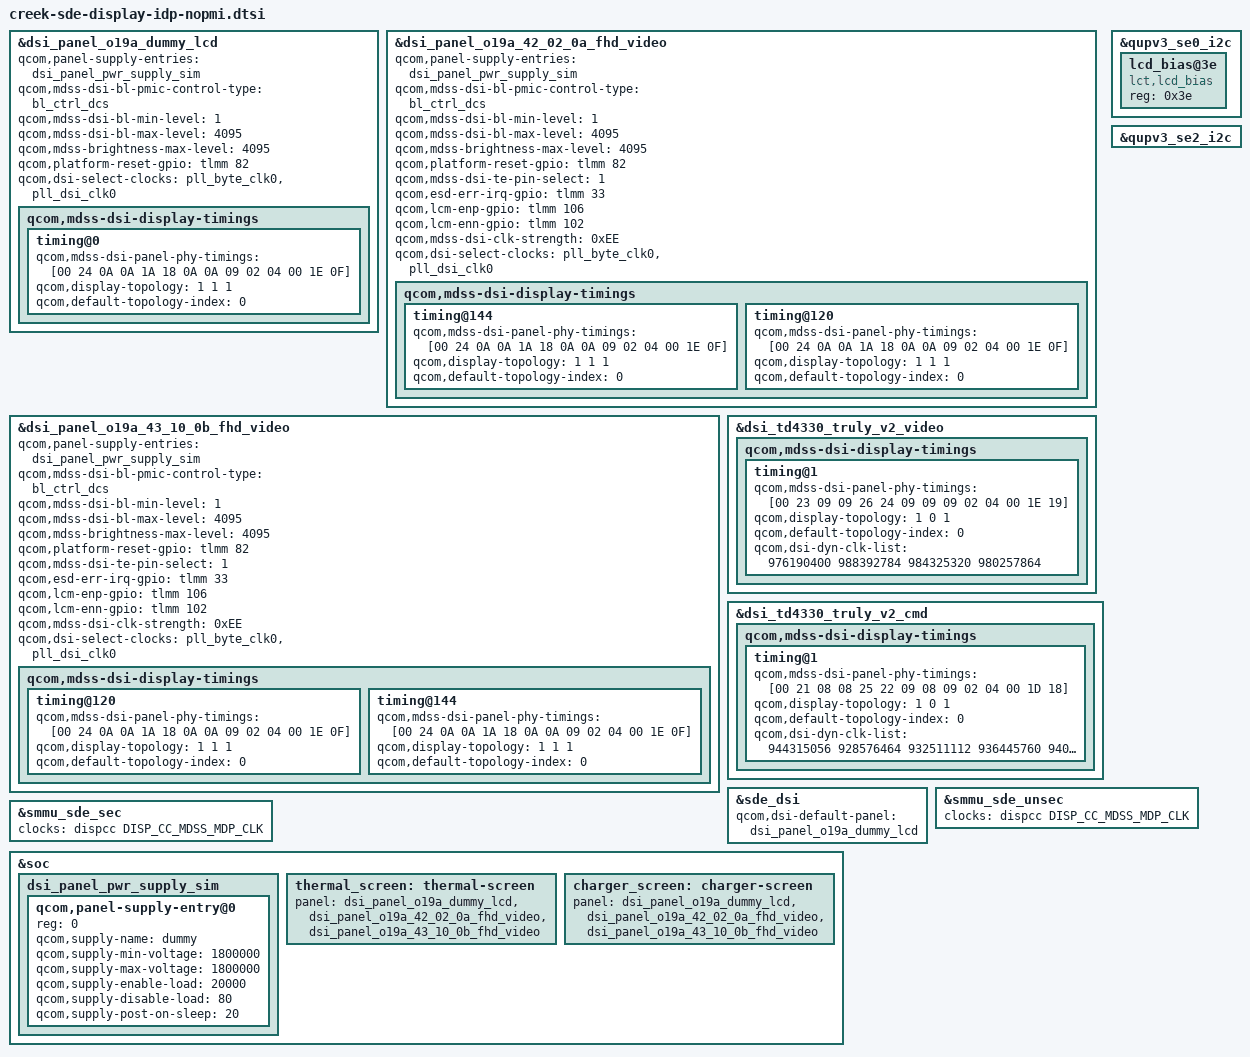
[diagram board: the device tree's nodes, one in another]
#include "dsi_panel_o19a_42_02_0a_fhd_video.dtsi"
#include "dsi_panel_o19a_43_10_0b_fhd_video.dtsi"
#include "dsi_panel_o19a_dummy_lcd.dtsi"
#include "xiaomi-sm6225-common.dtsi"
#include "touchscreen_o19a.dtsi"
#include "khaje-sde-display-idp-nopmi.dtsi"

&dsi_panel_o19a_dummy_lcd {
	qcom,panel-supply-entries = <&dsi_panel_pwr_supply_sim>;
	qcom,mdss-dsi-bl-pmic-control-type = "bl_ctrl_dcs";
	qcom,mdss-dsi-bl-min-level = <1>;
	qcom,mdss-dsi-bl-max-level = <4095>;
	qcom,mdss-brightness-max-level = <4095>;
	qcom,platform-reset-gpio = <&tlmm 82 0>;

	qcom,dsi-select-clocks = "pll_byte_clk0", "pll_dsi_clk0";
	qcom,mdss-dsi-display-timings {
		timing@0 {
			qcom,mdss-dsi-panel-phy-timings = [00 24 0A 0A 1A 18 0A
				0A 09 02 04 00 1E 0F];
			qcom,display-topology = <1 1 1>;
			qcom,default-topology-index = <0>;
		};
	};
};

&dsi_panel_o19a_42_02_0a_fhd_video {
	qcom,panel-supply-entries = <&dsi_panel_pwr_supply_sim>;
	qcom,mdss-dsi-bl-pmic-control-type = "bl_ctrl_dcs";
	qcom,mdss-dsi-bl-min-level = <1>;
	qcom,mdss-dsi-bl-max-level = <4095>;
	qcom,mdss-brightness-max-level = <4095>;
	qcom,platform-reset-gpio = <&tlmm 82 0>;
	qcom,mdss-dsi-te-pin-select = <1>;
	qcom,esd-err-irq-gpio = <&tlmm 33 0x2002>;
	qcom,lcm-enp-gpio = <&tlmm 106 0>;
	qcom,lcm-enn-gpio = <&tlmm 102 0>;
	qcom,mdss-dsi-clk-strength = <0xEE>;

	qcom,dsi-select-clocks = "pll_byte_clk0", "pll_dsi_clk0";
	qcom,mdss-dsi-display-timings {
		timing@144 {
			qcom,mdss-dsi-panel-phy-timings = [00 24 0A 0A 1A 18 0A
				0A 09 02 04 00 1E 0F];
			qcom,display-topology = <1 1 1>;
			qcom,default-topology-index = <0>;
		};
		timing@120 {
			qcom,mdss-dsi-panel-phy-timings = [00 24 0A 0A 1A 18 0A
				0A 09 02 04 00 1E 0F];
			qcom,display-topology = <1 1 1>;
			qcom,default-topology-index = <0>;
		};
	};
};

&dsi_panel_o19a_43_10_0b_fhd_video {
	qcom,panel-supply-entries = <&dsi_panel_pwr_supply_sim>;
	qcom,mdss-dsi-bl-pmic-control-type = "bl_ctrl_dcs";
	qcom,mdss-dsi-bl-min-level = <1>;
	qcom,mdss-dsi-bl-max-level = <4095>;
	qcom,mdss-brightness-max-level = <4095>;
	qcom,platform-reset-gpio = <&tlmm 82 0>;
	qcom,mdss-dsi-te-pin-select = <1>;
	qcom,esd-err-irq-gpio = <&tlmm 33 0x2002>;
	qcom,lcm-enp-gpio = <&tlmm 106 0>;
	qcom,lcm-enn-gpio = <&tlmm 102 0>;
	qcom,mdss-dsi-clk-strength = <0xEE>;

	qcom,dsi-select-clocks = "pll_byte_clk0", "pll_dsi_clk0";
	qcom,mdss-dsi-display-timings {
		timing@120 {
			qcom,mdss-dsi-panel-phy-timings = [00 24 0A 0A 1A 18 0A
				0A 09 02 04 00 1E 0F];
			qcom,display-topology = <1 1 1>;
			qcom,default-topology-index = <0>;
		};
		timing@144 {
			qcom,mdss-dsi-panel-phy-timings = [00 24 0A 0A 1A 18 0A
				0A 09 02 04 00 1E 0F];
			qcom,display-topology = <1 1 1>;
			qcom,default-topology-index = <0>;
		};
	};
};

&dsi_td4330_truly_v2_video {
	qcom,mdss-dsi-display-timings {
		timing@1 {
			qcom,mdss-dsi-panel-phy-timings = [00 23 09 09 26 24 09
					09 09 02 04 00 1E 19];
			qcom,display-topology = <1 0 1>;
			qcom,default-topology-index = <0>;
			qcom,dsi-dyn-clk-list =
				<976190400 988392784 984325320 980257864>;
		};
	};
};

&dsi_td4330_truly_v2_cmd {
	qcom,mdss-dsi-display-timings {
		timing@1 {
			qcom,mdss-dsi-panel-phy-timings = [00 21 08 08 25 22 09
					08 09 02 04 00 1D 18];
			qcom,display-topology = <1 0 1>;
			qcom,default-topology-index = <0>;
			qcom,dsi-dyn-clk-list =
				<944315056 928576464 932511112 936445760 940380400>;
		};
	};
};

&sde_dsi {
	qcom,dsi-default-panel = <&dsi_panel_o19a_dummy_lcd>;
};

/*panel bias i2c*/
&qupv3_se0_i2c {
	status = "okay";
	lcd_bias@3e {
		compatible = "lct,lcd_bias";
		reg = <0x3e>;
	};
};

&qupv3_se2_i2c {
    /delete-property/ qcom,i2c-touch-active;
    /delete-node/ synaptics_tcm@20;
    /delete-node/ novatek@62;
};

&smmu_sde_unsec {
	clocks = <&dispcc DISP_CC_MDSS_MDP_CLK>;
	clock-names = "mdp_core_clk";
};

&smmu_sde_sec {
	clocks = <&dispcc DISP_CC_MDSS_MDP_CLK>;
	clock-names = "mdp_core_clk";
};

&soc {
	dsi_panel_pwr_supply_sim: dsi_panel_pwr_supply_sim {
		#address-cells = <1>;
		#size-cells = <0>;

		qcom,panel-supply-entry@0 {
			reg = <0>;
			qcom,supply-name = "dummy";
			qcom,supply-min-voltage = <1800000>;
			qcom,supply-max-voltage = <1800000>;
			qcom,supply-enable-load = <20000>;
			qcom,supply-disable-load = <80>;
			qcom,supply-post-on-sleep = <20>;
		};
	};

	thermal_screen: thermal-screen {
		panel = <&dsi_panel_o19a_dummy_lcd &dsi_panel_o19a_42_02_0a_fhd_video &dsi_panel_o19a_43_10_0b_fhd_video>;
	};

	charger_screen: charger-screen {
		panel = <&dsi_panel_o19a_dummy_lcd &dsi_panel_o19a_42_02_0a_fhd_video &dsi_panel_o19a_43_10_0b_fhd_video>;
	};
};
